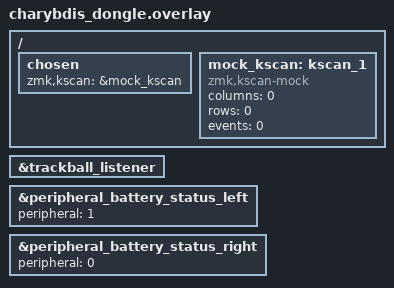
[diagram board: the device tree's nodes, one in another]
#include "charybdis.dtsi"
#include "split_input_common.dtsi"
/ {
    chosen {
        zmk,kscan = &mock_kscan;
    };

    mock_kscan: kscan_1 {
        compatible = "zmk,kscan-mock";
        columns = <0>;
        rows = <0>;
        events = <0>;
    };
};

&trackball_listener {
    status = "okay";
};

&peripheral_battery_status_left {
    peripheral = <1>;
};

&peripheral_battery_status_right {
    peripheral = <0>;
};
